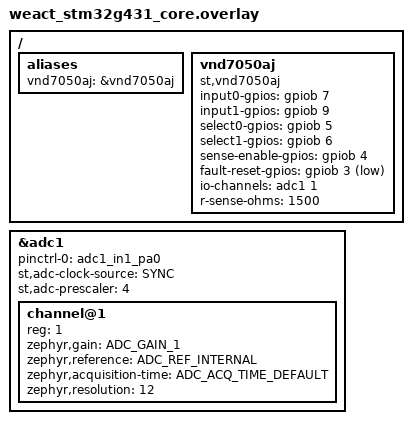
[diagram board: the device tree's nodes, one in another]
/*
 * Copyright (c) 2025, Eduard Iten
 * SPDX-License-Identifier: Apache-2.0
 */

/*
 * Devicetree overlay for VND7050AJ on weact_stm32g431_core
 */

/ {
	aliases {
		vnd7050aj = &vnd7050aj;
	};

	vnd7050aj: vnd7050aj {
		compatible = "st,vnd7050aj";
		status = "okay";

		/* Required properties */
		input0-gpios = <&gpiob 7 GPIO_ACTIVE_HIGH>;
		input1-gpios = <&gpiob 9 GPIO_ACTIVE_HIGH>;
		select0-gpios = <&gpiob 5 GPIO_ACTIVE_HIGH>;
		select1-gpios = <&gpiob 6 GPIO_ACTIVE_HIGH>;
		sense-enable-gpios = <&gpiob 4 GPIO_ACTIVE_HIGH>;
		fault-reset-gpios = <&gpiob 3 GPIO_ACTIVE_LOW>;
		io-channels = <&adc1 1>; /* PA0 */
		r-sense-ohms = <1500>;

		/* Optional properties */
		// k-factor = <1500>;
		// k-vcc = <8000>;
		// t-sense-0 = <25>;
		// v-sense-0 = <2070>;
		// k-tchip = <-5500>;
	};
};

&adc1 {
	status = "okay";
	pinctrl-0 = <&adc1_in1_pa0>;
	pinctrl-names = "default";
	st,adc-clock-source = "SYNC";
	st,adc-prescaler = <4>;
	#address-cells = <1>;
	#size-cells = <0>;

	channel@1 {
		reg = <1>;
		zephyr,gain = "ADC_GAIN_1";
		zephyr,reference = "ADC_REF_INTERNAL";
		zephyr,acquisition-time = <ADC_ACQ_TIME_DEFAULT>;
		zephyr,resolution = <12>;
	};
};
